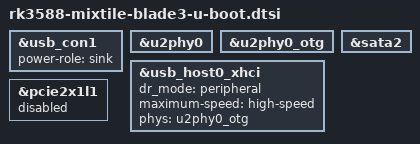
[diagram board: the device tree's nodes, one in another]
#include "rk3588-u-boot.dtsi"

/*
 * USB-C1 (FUSB302 on i2c1) is the power input. U-Boot only auto-probes a
 * TCPM whose connector is sink-only (see tcpm_post_bind()), so with the
 * upstream "dual" role PD would never be negotiated here, leaving the
 * source waiting until Linux starts talking PD.
 */
&usb_con1 {
	power-role = "sink";
};

/* Make the non-power USB port work with gadget/UMS */
&u2phy0 {
	status = "okay";
};

&u2phy0_otg {
	status = "okay";
};

&usb_host0_xhci {
	dr_mode = "peripheral";
	maximum-speed = "high-speed";
	phys = <&u2phy0_otg>;
	phy-names = "usb2-phy";
	status = "okay";
};

/*
 * The mini-PCIe socket shares combphy2_psu between pcie2x1l1 and sata2.
 * U-Boot has no use for mini-PCIe cards (Wi-Fi/LTE), so always run it as
 * SATA here to allow booting from an mSATA disk. Linux uses its own DT
 * (rockchip-rk3588-sata2 overlay to pick SATA) and re-initialises the PHY.
 */
&pcie2x1l1 {
	status = "disabled";
};

&sata2 {
	status = "okay";
};
